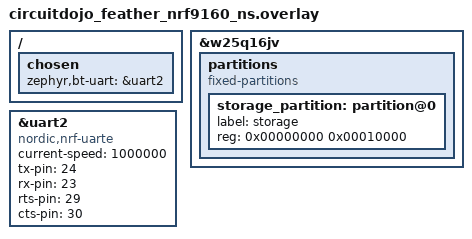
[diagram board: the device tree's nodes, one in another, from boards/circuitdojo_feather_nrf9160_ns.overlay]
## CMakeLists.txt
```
#
# Copyright (c) 2020 Circuit Dojo LLC
#
# SPDX-License-Identifier: Apache-2.0
#

cmake_minimum_required(VERSION 3.8.2)

find_package(Zephyr REQUIRED HINTS $ENV{ZEPHYR_BASE})

project(pyrinas_bridge)

target_sources(app PRIVATE src/main.c)
target_sources(app PRIVATE src/ble.c)
```

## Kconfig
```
# Copyright (c) 2017-2020 Linaro Limited
# Copyright (c) 2020 Arm Limited
#
# SPDX-License-Identifier: Apache-2.0
#

mainmenu "Pyrinas Configuration"

comment "Pyrinas-specific configuration options"

config HCI_NCP_RST_PORT
	string "Port connected to to reset for HCI device."
	default GPIO_0 if BOARD_CIRCUITDOJO_FEATHER_NRF9160_NS
	help
	  Pin used to reset external HCI device.

config HCI_NCP_RST_PIN
	int "Pin to reset external HCI device."
	default 0 if BOARD_CIRCUITDOJO_FEATHER_NRF9160_NS
	help
	  Pin used to reset external HCI device.

source "Kconfig.zephyr"
```

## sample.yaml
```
sample:
  name: nRF9160 Feather Test
  description: Testing all functionality internally to the nRF9160 Feather Board.
  platforms: all
tests:
  - test:
      build_only: true
      tags: samples tests
      min_ram: 16
```

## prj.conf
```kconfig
# Stackin' and heapin'
CONFIG_MAIN_STACK_SIZE=4096
CONFIG_HEAP_MEM_POOL_SIZE=4096

# Print a banner on the UART on startup.
CONFIG_BOOT_BANNER=y

# Enable console and printk()
CONFIG_PRINTK=y
CONFIG_STDOUT_CONSOLE=y

# Let __ASSERT do its job
CONFIG_DEBUG=y
CONFIG_LOG=y

# Enable Zephyr application to be booted by MCUboot
CONFIG_BOOTLOADER_MCUBOOT=y

# Adding Peripherals
CONFIG_GPIO=y
# CONFIG_I2C=y
# CONFIG_I2C_2=y

# SPI Related
# CONFIG_SPI=y
# CONFIG_SPI_NOR=y
# CONFIG_SPI_NOR_FLASH_LAYOUT_PAGE_SIZE=4096

# Enable flash operations.
# CONFIG_FLASH=y
# CONFIG_FLASH_MAP=y
# CONFIG_FLASH_PAGE_LAYOUT=y
# CONFIG_MPU_ALLOW_FLASH_WRITE=y # Note: only necessary for internal flash

# Nordic specific external flash stuff
# CONFIG_PM_EXTERNAL_FLASH=y
# CONFIG_PM_EXTERNAL_FLASH_DEV_NAME="w25q16jv"
# CONFIG_PM_EXTERNAL_FLASH_BASE=0x0
# CONFIG_PM_EXTERNAL_FLASH_SIZE=0x1000000

# Enable the LittleFS file system.
# CONFIG_FILE_SYSTEM=y
# CONFIG_FILE_SYSTEM_LITTLEFS=y

# BSD library
CONFIG_BSD_LIBRARY=y

# Network
CONFIG_NETWORKING=y
CONFIG_NET_NATIVE=n
CONFIG_NET_SOCKETS=y
CONFIG_NET_SOCKETS_OFFLOAD=y
CONFIG_MODEM_KEY_MGMT=y

# PDP Context
# CONFIG_LTE_LINK_CONTROL=y
# CONFIG_LTE_PDP_CMD=y
# CONFIG_LTE_PDP_CONTEXT="0,\"IP\",\"hologram\""

# AT host
CONFIG_AT_HOST_LIBRARY=y

# Enable Bluetooth stack and libraries
CONFIG_BT=y
CONFIG_BT_H4=y
CONFIG_BT_WAIT_NOP=y
CONFIG_BT_CENTRAL=y
CONFIG_BT_CTLR_PHY_CODED=y
CONFIG_BT_GATT_CLIENT=y
CONFIG_BT_GATT_DM=y
CONFIG_BT_SCAN=y
CONFIG_BT_SCAN_FILTER_ENABLE=y
CONFIG_BT_SCAN_UUID_CNT=1

CONFIG_BT_ECC=y
CONFIG_BT_SETTINGS=y
CONFIG_BT_SMP=y
CONFIG_BT_SIGNING=y
CONFIG_BT_MAX_PAIRED=8
CONFIG_BT_MAX_CONN=8
CONFIG_BT_PRIVACY=y
CONFIG_BT_LL_SW_SPLIT=y

CONFIG_UART_2_NRF_FLOW_CONTROL=y
CONFIG_UART_INTERRUPT_DRIVEN=y
CONFIG_HCI_NCP_RST_PIN=0
```

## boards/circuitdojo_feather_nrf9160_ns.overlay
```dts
/*
 * Copyright (c) 2020 Circuit Dojo LLC
 *
 * SPDX-License-Identifier: Apache-2.0
 */

/delete-node/ &storage_partition;

&w25q16jv {
	partitions {
		compatible = "fixed-partitions";
		#address-cells = <1>;
		#size-cells = <1>;

		storage_partition: partition@0 {
			label = "storage";
			reg = <0x00000000 0x00010000>;
		};
	};
};

/ {
	chosen {
		zephyr,bt-uart=&uart2;
	};

};

&uart2 {
	compatible = "nordic,nrf-uarte";
	current-speed = <1000000>;
	status = "okay";
	tx-pin = <24>;
	rx-pin = <23>;
	rts-pin = <29>;
	cts-pin = <30>;
};
```

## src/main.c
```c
/*
 * Copyright (c) 2020 Circuit Dojo LLC
 *
 * SPDX-License-Identifier: Apache-2.0
 */

#include <zephyr.h>
#include <sys/printk.h>
#include <device.h>
#include <devicetree.h>
#include <drivers/gpio.h>
#include <drivers/i2c.h>

#include "ble.h"

/* 1000 msec = 1 sec */
#define SLEEP_TIME_MS 1000

/* The devicetree node identifier for the "led0" alias. */
#define LED0_NODE DT_ALIAS(led0)

#if DT_NODE_HAS_STATUS(LED0_NODE, okay)
#define LED0 DT_GPIO_LABEL(LED0_NODE, gpios)
#define PIN DT_GPIO_PIN(LED0_NODE, gpios)
#if DT_PHA_HAS_CELL(LED0_NODE, gpios, flags)
#define FLAGS DT_GPIO_FLAGS(LED0_NODE, gpios)
#endif
#else
/* A build error here means your board isn't set up to blink an LED. */
#error "Unsupported board: led0 devicetree alias is not defined"
#define LED0 ""
#define PIN 0
#endif
/* PCF8506 Address*/
#define PCF8506_I2C_ADDR 0x51

#ifndef FLAGS
#define FLAGS 0
#endif

struct device *blue_led;

static void buttons_leds_init(void)
{
	/*
	 * Set up LED
	 */
	int ret;

	blue_led = device_get_binding(LED0);
	__ASSERT(dev == NULL, "unable to get binding.");

	ret = gpio_pin_configure(blue_led, PIN, GPIO_OUTPUT_ACTIVE | FLAGS);
	__ASSERT(ret == 0, "unable to configure pin: %d", err);

	/*
	 * Set up button
	 */
}

void main(void)
{
	printk("Pyrinas %s running on %s!\n", "central", CONFIG_BOARD);

	/* Init buttons and LEDs */
	buttons_leds_init();

	/* BLE initialization */
	ble_init();

	while (1)
	{
		gpio_pin_toggle(blue_led, PIN);
		k_msleep(SLEEP_TIME_MS);
	}
}
```

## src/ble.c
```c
/*
 * Copyright (c) 2020 Circuit Dojo LLC
 * Copyright (c) 2018 Nordic Semiconductor ASA
 *
 * SPDX-License-Identifier: LicenseRef-BSD-5-Clause-Nordic
 */

#include <zephyr.h>

#include <device.h>
#include <devicetree.h>

#include <drivers/gpio.h>

#include <bluetooth/gatt.h>
#include <bluetooth/uuid.h>
#include <bluetooth/gatt_dm.h>
#include <bluetooth/scan.h>

#include <sys/byteorder.h>

#include "ble.h"

/* Thinghy advertisement UUID */
#define BT_UUID_THINGY                                                \
	BT_UUID_DECLARE_128(0x42, 0x00, 0x74, 0xA9, 0xFF, 0x52, 0x10, 0x9B, \
											0x33, 0x49, 0x35, 0x9B, 0x00, 0x01, 0x68, 0xEF)

/* Pyrinas service UUID */
#define BT_UUID_TMS                                                   \
	BT_UUID_DECLARE_128(0x42, 0x00, 0x74, 0xA9, 0xFF, 0x52, 0x10, 0x9B, \
											0x33, 0x49, 0x35, 0x9B, 0x00, 0x04, 0x68, 0xEF)

/* Thingy characteristic UUID */
#define BT_UUID_TOC                                                   \
	BT_UUID_DECLARE_128(0x42, 0x00, 0x74, 0xA9, 0xFF, 0x52, 0x10, 0x9B, \
											0x33, 0x49, 0x35, 0x9B, 0x03, 0x04, 0x68, 0xEF)

// Callbacks that get associated with `scan_cb`
// BT_SCAN_CB_INIT(scan_cb, scan_filter_match, NULL, NULL, NULL);

/* Storing static config*/
static ble_init_t m_config;

void scan_start(void)
{
	int err;

	// Active scanning with phy coded enabled
	struct bt_le_scan_param scan_param = {
			.type = BT_LE_SCAN_TYPE_ACTIVE,
			.options = BT_LE_SCAN_OPT_CODED,
			.interval = BT_GAP_SCAN_FAST_INTERVAL,
			.window = BT_GAP_SCAN_FAST_WINDOW,
	};

	struct bt_scan_init_param scan_init = {
			.connect_if_match = 1,
			.scan_param = &scan_param,
			.conn_param = BT_LE_CONN_PARAM_DEFAULT,
	};

	bt_scan_init(&scan_init);

	err = bt_scan_filter_add(BT_SCAN_FILTER_TYPE_UUID, BT_UUID_THINGY);
	if (err)
	{
		printk("Scanning filters cannot be set\n");
		return;
	}

	err = bt_scan_filter_enable(BT_SCAN_UUID_FILTER, false);
	if (err)
	{
		printk("Filters cannot be turned on\n");
	}

	err = bt_scan_start(BT_SCAN_TYPE_SCAN_ACTIVE);
	if (err)
	{
		printk("Scanning failed to start, err %d\n", err);
	}

	printk("Scanning...\n");
}

static void discovery_completed(struct bt_gatt_dm *disc, void *ctx)
{
	int err;

	printk("Discovery complete!\n");

release:
	err = bt_gatt_dm_data_release(disc);
	if (err)
	{
		printk("Could not release discovery data, err: %d\n", err);
	}
}

static void discovery_service_not_found(struct bt_conn *conn, void *ctx)
{
	printk("Thingy orientation service not found!\n");
}

static void discovery_error_found(struct bt_conn *conn, int err, void *ctx)
{
	printk("The discovery procedure failed, err %d\n", err);
}

static struct bt_gatt_dm_cb discovery_cb = {
		.completed = discovery_completed,
		.service_not_found = discovery_service_not_found,
		.error_found = discovery_error_found,
};

static void connected(struct bt_conn *conn, u8_t conn_err)
{
	char addr[BT_ADDR_LE_STR_LEN];
	int err;

	bt_addr_le_to_str(bt_conn_get_dst(conn), addr, sizeof(addr));

	// Return if there's a connection error
	if (conn_err)
	{
		printk("Failed to connect: %d\n", conn_err);
		return;
	}

	printk("Connected: %s\n", addr);

	err = bt_gatt_dm_start(conn, BT_UUID_TMS, &discovery_cb, NULL);
	if (err)
	{
		printk("Could not start service discovery, err %d\n", err);
	}
}

static void disconnected(struct bt_conn *conn, u8_t reason)
{
	char addr[BT_ADDR_LE_STR_LEN];

	bt_addr_le_to_str(bt_conn_get_dst(conn), addr, sizeof(addr));

	printk("Disconnected: %s (reason 0x%02x)\n", addr, reason);

	// Start scanning again and re-connect if foudn
	scan_start();
}

static struct bt_conn_cb conn_callbacks = {
		.connected = connected,
		.disconnected = disconnected,
};

static void ble_ready(int err)
{
	printk("Bluetooth ready\n");

	bt_conn_cb_register(&conn_callbacks);
	scan_start();
}

void ble_init(ble_init_t *p_init)
{
	int err;

	// Throw an error if NULL
	if (p_init == NULL)
	{
		__ASSERT(port, "Error: Invalid param.\n");
	}

	// Get the port involved
	struct device *port;
	port = device_get_binding(CONFIG_HCI_NCP_RST_PORT);
	__ASSERT(port, "Error: Bad port for boot HCI reset.\n");

	err = gpio_pin_configure(port, CONFIG_HCI_NCP_RST_PIN, GPIO_OUTPUT_INACTIVE);
	__ASSERT(err == 0, "Error: Unable to configure pin: %d", err);

	printk("Initializing Bluetooth..\n");
	err = bt_enable(ble_ready);
	__ASSERT(err == 0, "Error: Bluetooth init failed (err %d)\n", err);

	// Delay so both IC's are in sync
	k_msleep(1000);

	// Release
	err = gpio_pin_configure(port, CONFIG_HCI_NCP_RST_PIN, GPIO_DISCONNECTED);
	__ASSERT(err == 0, "Error: Unable to configure pin: %d", err);
}
```

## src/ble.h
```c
/*
 * Copyright (c) 202 Circuit Dojo LLC
 *
 * SPDX-License-Identifier: Apache-2.0
 */

#ifndef _BLE_H_
#define _BLE_H_

#include "ble_handlers.h"
#include "proto/command.pb.h"

/**@brief Different device "modes"
 */
typedef enum
{
  ble_mode_peripheral = 0,
  ble_mode_central = 1,
} ble_mode_t;

/**@brief BLE callback function to main context.
 */

/**@brief Struct for initialization of BLE stack.
 */
typedef struct
{
  ble_mode_t mode;
  bool long_range;
  // union {
  //   ble_central_init_t config;
  // };

} ble_init_t;

#define BLE_STACK_PERIPH_DEF(X) ble_init_t X = {.mode = ble_mode_peripheral, .long_range = true}
#define BLE_STACK_CENTRAL_DEF(X) ble_init_t X = {.mode = ble_mode_central, .long_range = true}

/**@brief Function for terminating connection with a BLE peripheral device.
 */
void ble_disconnect(void);

/**@brief Function for initializing the BLE stack.
 */
void ble_init(ble_init_t *init);

/**@brief Function for starting the scanning.
 */
void scan_start(void);

/**@brief Function for publishing.
 */
void ble_publish(char *name, char *data);

// TODO: document this
void ble_publish_raw(protobuf_event_t event);

// TODO: document this
void ble_subscribe(char *name, susbcribe_handler_t handler);

// TODO: document this
void ble_subscribe_raw(raw_susbcribe_handler_t handler);

// TODO: document this
void advertising_start(void);

/**@brief Function for checking the connection state.
 *
 * @retval true     If peripheral device is connected.
 * @retval false    If peripheral device is not connected.
 */
bool ble_is_connected(void);

// TODO: document this
void ble_process();

#endif /* _BLE_H_ */
```

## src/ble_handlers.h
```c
/**
 *
 * Copyright (c) 2020, Jared Wolff
 * All rights reserved.
 *
 * Redistribution and use in source and binary forms, with or without
 * modification, are permitted provided that the following conditions are met:
 *
 * 1. Redistributions of source code must retain the above copyright notice, this
 *    list of conditions and the following disclaimer.
 *
 * 2. Redistributions in binary form must reproduce the above copyright notice,
 *    this list of conditions and the following disclaimer in the documentation
 *    and/or other materials provided with the distribution.
 *
 * 3. Neither the name of the copyright holder nor the names of its
 *    contributors may be used to endorse or promote products derived from
 *    this software without specific prior written permission.
 *
 * THIS SOFTWARE IS PROVIDED BY THE COPYRIGHT HOLDERS AND CONTRIBUTORS "AS IS"
 * AND ANY EXPRESS OR IMPLIED WARRANTIES, INCLUDING, BUT NOT LIMITED TO, THE
 * IMPLIED WARRANTIES OF MERCHANTABILITY AND FITNESS FOR A PARTICULAR PURPOSE ARE
 * DISCLAIMED. IN NO EVENT SHALL THE COPYRIGHT HOLDER OR CONTRIBUTORS BE LIABLE
 * FOR ANY DIRECT, INDIRECT, INCIDENTAL, SPECIAL, EXEMPLARY, OR CONSEQUENTIAL
 * DAMAGES (INCLUDING, BUT NOT LIMITED TO, PROCUREMENT OF SUBSTITUTE GOODS OR
 * SERVICES; LOSS OF USE, DATA, OR PROFITS; OR BUSINESS INTERRUPTION) HOWEVER
 * CAUSED AND ON ANY THEORY OF LIABILITY, WHETHER IN CONTRACT, STRICT LIABILITY,
 * OR TORT (INCLUDING NEGLIGENCE OR OTHERWISE) ARISING IN ANY WAY OUT OF THE USE
 * OF THIS SOFTWARE, EVEN IF ADVISED OF THE POSSIBILITY OF SUCH DAMAGE.
 *
 */

#ifndef BLE_HANDLERS_H
#define BLE_HANDLERS_H

#include "proto/command.pb.h"

// TODO: duplicate handlers that are doing the same thing as Central and Peripheral
/**@brief Subscription handler definition. */
typedef void (*susbcribe_handler_t)(char *name, char *data);

/**@brief Raw subscription handler definition. */
typedef void (*raw_susbcribe_handler_t)(protobuf_event_t *evt);

#endif
```
